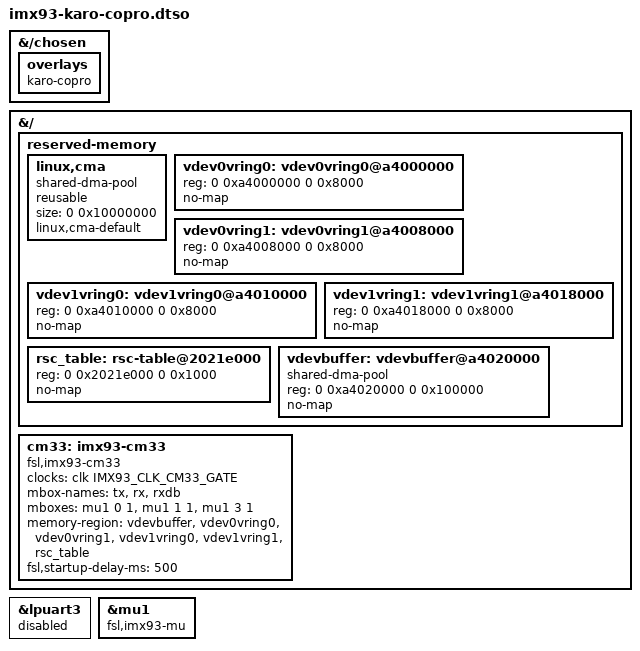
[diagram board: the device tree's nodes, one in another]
// SPDX-License-Identifier: (GPL-2.0+ OR MIT)
/*
 * Copyright (C) 2024 Uwe Steinkohl <us@karo-electronics.de>
 */
#include <dt-bindings/interrupt-controller/arm-gic.h>
#include <dt-bindings/clock/imx93-clock.h>

/dts-v1/;

/plugin/;

&{/chosen} {
	overlays {
		karo-copro;
	};
};

&{/} {
	reserved-memory {
		#address-cells = <2>;
		#size-cells = <2>;
		ranges;

		linux,cma {
			compatible = "shared-dma-pool";
			reusable;
			size = <0 0x10000000>;
			linux,cma-default;
		};

		vdev0vring0: vdev0vring0@a4000000 {
			reg = <0 0xa4000000 0 0x8000>;
			no-map;
		};

		vdev0vring1: vdev0vring1@a4008000 {
			reg = <0 0xa4008000 0 0x8000>;
			no-map;
		};

		vdev1vring0: vdev1vring0@a4010000 {
			reg = <0 0xa4010000 0 0x8000>;
			no-map;
		};

		vdev1vring1: vdev1vring1@a4018000 {
			reg = <0 0xa4018000 0 0x8000>;
			no-map;
		};

		rsc_table: rsc-table@2021e000 {
			reg = <0 0x2021e000 0 0x1000>;
			no-map;
		};

		vdevbuffer: vdevbuffer@a4020000 {
			compatible = "shared-dma-pool";
			reg = <0 0xa4020000 0 0x100000>;
			no-map;
		};
	};

	cm33: imx93-cm33 {
		compatible = "fsl,imx93-cm33";
		clocks = <&clk IMX93_CLK_CM33_GATE>;
		mbox-names = "tx", "rx", "rxdb";
		mboxes = <&mu1 0 1
			  &mu1 1 1
			  &mu1 3 1>;
		memory-region = <&vdevbuffer>, <&vdev0vring0>, <&vdev0vring1>,
				<&vdev1vring0>, <&vdev1vring1>, <&rsc_table>;
		fsl,startup-delay-ms = <500>;
	};
};

/*
&clk {
	init-on-array = <
			 IMX93_CLK_M33
			>;
};
*/



&lpuart3 {
	status = "disabled";
};

&mu1 {
	compatible = "fsl,imx93-mu", "fsl,imx8ulp-mu";
	status = "okay";
};


